AUTOSAR XML (schema 4-2-2)
package /UAES/ASW
  swc implementation Implementation: programming-language=C, sw-version=1.30.1, used-code-generator=Embedded Coder 7.1 (R2018b) 24-May-2018, vendor-id=0, behavior=InternalBehavior
    code-descriptors:
      code Code
        artifact-descriptors:
          short-label=IntLamp_ComCnvTx_c, category=SWSRC
          short-label=IntLamp_ComCnvTx_h, category=SWHDR
          short-label=rtwtypes_h, category=SWHDR
    resource consumption RsrcCons_IntLamp_ComCnvTx
package /UAES/ASW/SwComponentTypes
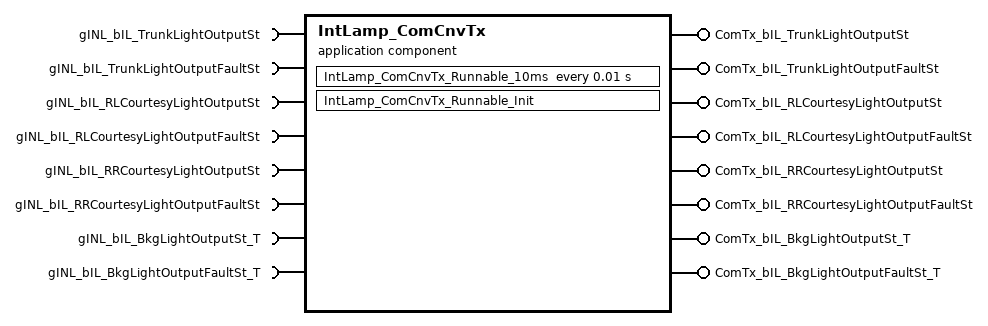
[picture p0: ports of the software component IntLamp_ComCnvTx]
  application sw component type IntLamp_ComCnvTx
    8 x require port:
      gINL_bIL_TrunkLightOutputSt: nonqueued-receiver-com-spec{data-element=gINL_bIL_TrunkLightOutputSt/Val, init-value=0}, required-interface=gINL_bIL_TrunkLightOutputSt
      gINL_bIL_TrunkLightOutputFaultSt: nonqueued-receiver-com-spec{data-element=gINL_bIL_TrunkLightOutputFaultSt/Val, init-value=0}, required-interface=gINL_bIL_TrunkLightOutputFaultSt
      gINL_bIL_RLCourtesyLightOutputSt: nonqueued-receiver-com-spec{data-element=gINL_bIL_RLCourtesyLightOutputSt/Val, init-value=0}, required-interface=gINL_bIL_RLCourtesyLightOutputSt
      gINL_bIL_RLCourtesyLightOutputFaultSt: nonqueued-receiver-com-spec{data-element=gINL_bIL_RLCourtesyLightOutputFaultSt/Val, init-value=0}, required-interface=gINL_bIL_RLCourtesyLightOutputFaultSt
      gINL_bIL_RRCourtesyLightOutputSt: nonqueued-receiver-com-spec{data-element=gINL_bIL_RRCourtesyLightOutputSt/Val, init-value=0}, required-interface=gINL_bIL_RRCourtesyLightOutputSt
      gINL_bIL_RRCourtesyLightOutputFaultSt: nonqueued-receiver-com-spec{data-element=gINL_bIL_RRCourtesyLightOutputFaultSt/Val, init-value=0}, required-interface=gINL_bIL_RRCourtesyLightOutputFaultSt
      gINL_bIL_BkgLightOutputSt_T: nonqueued-receiver-com-spec{data-element=gINL_bIL_BkgLightOutputSt_T/Val, init-value=0}, required-interface=gINL_bIL_BkgLightOutputSt_T
      gINL_bIL_BkgLightOutputFaultSt_T: nonqueued-receiver-com-spec{data-element=gINL_bIL_BkgLightOutputFaultSt_T/Val, init-value=0}, required-interface=gINL_bIL_BkgLightOutputFaultSt_T
    8 x provide port:
      ComTx_bIL_TrunkLightOutputSt: nonqueued-sender-com-spec{data-element=ComTx_bIL_TrunkLightOutputSt/Val, init-value=0}, provided-interface=ComTx_bIL_TrunkLightOutputSt
      ComTx_bIL_TrunkLightOutputFaultSt: nonqueued-sender-com-spec{data-element=ComTx_bIL_TrunkLightOutputFaultSt/Val, init-value=0}, provided-interface=ComTx_bIL_TrunkLightOutputFaultSt
      ComTx_bIL_RLCourtesyLightOutputSt: nonqueued-sender-com-spec{data-element=ComTx_bIL_RLCourtesyLightOutputSt/Val, init-value=0}, provided-interface=ComTx_bIL_RLCourtesyLightOutputSt
      ComTx_bIL_RLCourtesyLightOutputFaultSt: nonqueued-sender-com-spec{data-element=ComTx_bIL_RLCourtesyLightOutputFaultSt/Val, init-value=0}, provided-interface=ComTx_bIL_RLCourtesyLightOutputFaultSt
      ComTx_bIL_RRCourtesyLightOutputSt: nonqueued-sender-com-spec{data-element=ComTx_bIL_RRCourtesyLightOutputSt/Val, init-value=0}, provided-interface=ComTx_bIL_RRCourtesyLightOutputSt
      ComTx_bIL_RRCourtesyLightOutputFaultSt: nonqueued-sender-com-spec{data-element=ComTx_bIL_RRCourtesyLightOutputFaultSt/Val, init-value=0}, provided-interface=ComTx_bIL_RRCourtesyLightOutputFaultSt
      ComTx_bIL_BkgLightOutputSt_T: nonqueued-sender-com-spec{data-element=ComTx_bIL_BkgLightOutputSt_T/Val, init-value=0}, provided-interface=ComTx_bIL_BkgLightOutputSt_T
      ComTx_bIL_BkgLightOutputFaultSt_T: nonqueued-sender-com-spec{data-element=ComTx_bIL_BkgLightOutputFaultSt_T/Val, init-value=0}, provided-interface=ComTx_bIL_BkgLightOutputFaultSt_T
    behavior InternalBehavior: handle-termination-and-restart=NO-SUPPORT
      init event IntLamp_ComCnvTx_InitEvent: start-on-event=IntLamp_ComCnvTx_Runnable_Init
      timing event TMT_IntLamp_ComCnvTx_Runnable_10ms: start-on-event=IntLamp_ComCnvTx_Runnable_10ms, period=0.01
      runnable IntLamp_ComCnvTx_Runnable_Init
      runnable IntLamp_ComCnvTx_Runnable_10ms
        data-receive-point-by-arguments:
          8 x access:
            IN_gINL_bIL_BkgLightOutputFaultSt_T_Val: accessed-variable=gINL_bIL_BkgLightOutputFaultSt_T.Val
            IN_gINL_bIL_BkgLightOutputSt_T_Val: accessed-variable=gINL_bIL_BkgLightOutputSt_T.Val
            IN_gINL_bIL_RLCourtesyLightOutputFaultSt_Val: accessed-variable=gINL_bIL_RLCourtesyLightOutputFaultSt.Val
            IN_gINL_bIL_RLCourtesyLightOutputSt_Val: accessed-variable=gINL_bIL_RLCourtesyLightOutputSt.Val
            IN_gINL_bIL_RRCourtesyLightOutputFaultSt_Val: accessed-variable=gINL_bIL_RRCourtesyLightOutputFaultSt.Val
            IN_gINL_bIL_RRCourtesyLightOutputSt_Val: accessed-variable=gINL_bIL_RRCourtesyLightOutputSt.Val
            IN_gINL_bIL_TrunkLightOutputFaultSt_Val: accessed-variable=gINL_bIL_TrunkLightOutputFaultSt.Val
            IN_gINL_bIL_TrunkLightOutputSt_Val: accessed-variable=gINL_bIL_TrunkLightOutputSt.Val
        data-send-points:
          8 x access:
            OUT_ComTx_bIL_TrunkLightOutputSt_Val: accessed-variable=ComTx_bIL_TrunkLightOutputSt.Val
            OUT_ComTx_bIL_TrunkLightOutputFaultSt_Val: accessed-variable=ComTx_bIL_TrunkLightOutputFaultSt.Val
            OUT_ComTx_bIL_RLCourtesyLightOutputSt_Val: accessed-variable=ComTx_bIL_RLCourtesyLightOutputSt.Val
            OUT_ComTx_bIL_RLCourtesyLightOutputFaultSt_Val: accessed-variable=ComTx_bIL_RLCourtesyLightOutputFaultSt.Val
            OUT_ComTx_bIL_RRCourtesyLightOutputSt_Val: accessed-variable=ComTx_bIL_RRCourtesyLightOutputSt.Val
            OUT_ComTx_bIL_RRCourtesyLightOutputFaultSt_Val: accessed-variable=ComTx_bIL_RRCourtesyLightOutputFaultSt.Val
            OUT_ComTx_bIL_BkgLightOutputSt_T_Val: accessed-variable=ComTx_bIL_BkgLightOutputSt_T.Val
            OUT_ComTx_bIL_BkgLightOutputFaultSt_T_Val: accessed-variable=ComTx_bIL_BkgLightOutputFaultSt_T.Val
package /UAES/ASW/PortInterfaces
  16 x sender receiver interface:
    gINL_bIL_TrunkLightOutputSt
      data Val: category=VALUE, sw-calibration-access=READ-ONLY, type=boolean
    gINL_bIL_TrunkLightOutputFaultSt
      data Val: category=VALUE, sw-calibration-access=READ-ONLY, type=boolean
    gINL_bIL_RLCourtesyLightOutputSt
      data Val: category=VALUE, sw-calibration-access=READ-ONLY, type=boolean
    gINL_bIL_RLCourtesyLightOutputFaultSt
      data Val: category=VALUE, sw-calibration-access=READ-ONLY, type=boolean
    gINL_bIL_RRCourtesyLightOutputSt
      data Val: category=VALUE, sw-calibration-access=READ-ONLY, type=boolean
    gINL_bIL_RRCourtesyLightOutputFaultSt
      data Val: category=VALUE, sw-calibration-access=READ-ONLY, type=boolean
    gINL_bIL_BkgLightOutputSt_T
      data Val: category=VALUE, sw-calibration-access=READ-ONLY, type=boolean
    gINL_bIL_BkgLightOutputFaultSt_T
      data Val: category=VALUE, sw-calibration-access=READ-ONLY, type=boolean
    ComTx_bIL_TrunkLightOutputSt
      data Val: category=VALUE, sw-calibration-access=READ-ONLY, type=boolean
    ComTx_bIL_TrunkLightOutputFaultSt
      data Val: category=VALUE, sw-calibration-access=READ-ONLY, type=boolean
    ComTx_bIL_RLCourtesyLightOutputSt
      data Val: category=VALUE, sw-calibration-access=READ-ONLY, type=boolean
    ComTx_bIL_RLCourtesyLightOutputFaultSt
      data Val: category=VALUE, sw-calibration-access=READ-ONLY, type=boolean
    ComTx_bIL_RRCourtesyLightOutputSt
      data Val: category=VALUE, sw-calibration-access=READ-ONLY, type=boolean
    ComTx_bIL_RRCourtesyLightOutputFaultSt
      data Val: category=VALUE, sw-calibration-access=READ-ONLY, type=boolean
    ComTx_bIL_BkgLightOutputSt_T
      data Val: category=VALUE, sw-calibration-access=READ-ONLY, type=boolean
    ComTx_bIL_BkgLightOutputFaultSt_T
      data Val: category=VALUE, sw-calibration-access=READ-ONLY, type=boolean
